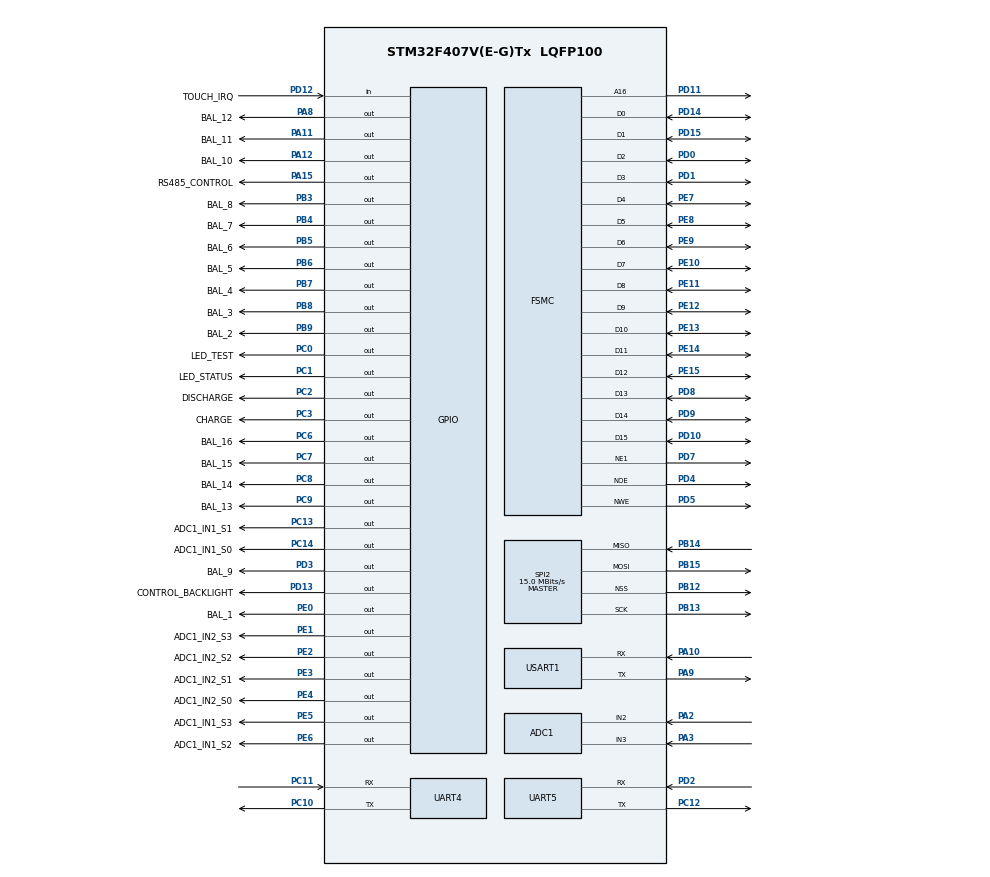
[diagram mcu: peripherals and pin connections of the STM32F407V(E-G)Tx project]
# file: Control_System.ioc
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ADC1.Channel-1\#ChannelRegularConversion=ADC_CHANNEL_2
ADC1.NbrOfConversionFlag=1
ADC1.Rank-1\#ChannelRegularConversion=1
ADC1.SamplingTime-1\#ChannelRegularConversion=ADC_SAMPLETIME_3CYCLES
ADC1.master=1
FSMC.AddressSetupTime1=0
FSMC.BusTurnAroundDuration1=0
FSMC.DataSetupTime1=1
Mcu.Family=STM32F4
Mcu.Name=STM32F407V(E-G)Tx
Mcu.Package=LQFP100
NVIC.PriorityGroup=NVIC_PRIORITYGROUP_4
PA10.Mode=Asynchronous
PA10.Signal=USART1_RX
PA11.GPIO_Label=BAL_11
PA11.Signal=GPIO_Output
PA12.GPIO_Label=BAL_10
PA12.Signal=GPIO_Output
PA13.Mode=Serial_Wire
PA13.Signal=SYS_JTMS-SWDIO
PA14.Mode=Serial_Wire
PA14.Signal=SYS_JTCK-SWCLK
PA15.GPIO_Label=RS485_CONTROL
PA15.Signal=GPIO_Output
PA2.Signal=ADCx_IN2
PA3.Signal=ADCx_IN3
PA8.GPIO_Label=BAL_12
PA8.Signal=GPIO_Output
PA9.Mode=Asynchronous
PA9.Signal=USART1_TX
PB12.Mode=NSS_Signal_Hard_Output
PB12.Signal=SPI2_NSS
PB13.Mode=Full_Duplex_Master
PB13.Signal=SPI2_SCK
PB14.Mode=Full_Duplex_Master
PB14.Signal=SPI2_MISO
PB15.Mode=Full_Duplex_Master
PB15.Signal=SPI2_MOSI
PB3.GPIO_Label=BAL_8
PB3.Signal=GPIO_Output
PB4.GPIO_Label=BAL_7
PB4.Signal=GPIO_Output
PB5.GPIO_Label=BAL_6
PB5.Signal=GPIO_Output
PB6.GPIO_Label=BAL_5
PB6.Signal=GPIO_Output
PB7.GPIO_Label=BAL_4
PB7.Signal=GPIO_Output
PB8.GPIO_Label=BAL_3
PB8.Signal=GPIO_Output
PB9.GPIO_Label=BAL_2
PB9.Signal=GPIO_Output
PC0.GPIO_Label=LED_TEST
PC0.Signal=GPIO_Output
PC1.GPIO_Label=LED_STATUS
PC1.Signal=GPIO_Output
PC10.Mode=Asynchronous
PC10.Signal=UART4_TX
PC11.Mode=Asynchronous
PC11.Signal=UART4_RX
PC12.Mode=Asynchronous
PC12.Signal=UART5_TX
PC13-ANTI_TAMP.GPIO_Label=ADC1_IN1_S1
PC13-ANTI_TAMP.Signal=GPIO_Output
PC14-OSC32_IN.GPIO_Label=ADC1_IN1_S0
PC14-OSC32_IN.Signal=GPIO_Output
PC2.GPIO_Label=DISCHARGE
PC2.Signal=GPIO_Output
PC3.GPIO_Label=CHARGE
PC3.Signal=GPIO_Output
PC6.GPIO_Label=BAL_16
PC6.Signal=GPIO_Output
PC7.GPIO_Label=BAL_15
PC7.Signal=GPIO_Output
PC8.GPIO_Label=BAL_14
PC8.Signal=GPIO_Output
PC9.GPIO_Label=BAL_13
PC9.Signal=GPIO_Output
PD0.Mode=16b-d1
PD0.Signal=FSMC_D2
PD1.Mode=16b-d1
PD1.Signal=FSMC_D3
PD10.Mode=16b-d1
PD10.Signal=FSMC_D15
PD11.Mode=A16_1
PD11.Signal=FSMC_A16
PD12.GPIO_Label=TOUCH_IRQ
PD12.Signal=GPIO_Input
PD13.GPIO_Label=CONTROL_BACKLIGHT
PD13.Signal=GPIO_Output
PD14.Mode=16b-d1
PD14.Signal=FSMC_D0
PD15.Mode=16b-d1
PD15.Signal=FSMC_D1
PD2.Mode=Asynchronous
PD2.Signal=UART5_RX
PD3.GPIO_Label=BAL_9
PD3.Signal=GPIO_Output
PD4.Mode=Lcd1
PD4.Signal=FSMC_NOE
PD5.Mode=Lcd1
PD5.Signal=FSMC_NWE
PD7.Mode=NorPsramChipSelect1_1
PD7.Signal=FSMC_NE1
PD8.Mode=16b-d1
PD8.Signal=FSMC_D13
PD9.Mode=16b-d1
PD9.Signal=FSMC_D14
PE0.GPIO_Label=BAL_1
PE0.Signal=GPIO_Output
PE1.GPIO_Label=ADC1_IN2_S3
PE1.Signal=GPIO_Output
PE10.Mode=16b-d1
PE10.Signal=FSMC_D7
PE11.Mode=16b-d1
PE11.Signal=FSMC_D8
PE12.Mode=16b-d1
PE12.Signal=FSMC_D9
PE13.Mode=16b-d1
PE13.Signal=FSMC_D10
PE14.Mode=16b-d1
PE14.Signal=FSMC_D11
PE15.Mode=16b-d1
PE15.Signal=FSMC_D12
PE2.GPIO_Label=ADC1_IN2_S2
PE2.Signal=GPIO_Output
PE3.GPIO_Label=ADC1_IN2_S1
PE3.Signal=GPIO_Output
PE4.GPIO_Label=ADC1_IN2_S0
PE4.Signal=GPIO_Output
PE5.GPIO_Label=ADC1_IN1_S3
PE5.Signal=GPIO_Output
PE6.GPIO_Label=ADC1_IN1_S2
PE6.Signal=GPIO_Output
PE7.Mode=16b-d1
PE7.Signal=FSMC_D4
PE8.Mode=16b-d1
PE8.Signal=FSMC_D5
PE9.Mode=16b-d1
PE9.Signal=FSMC_D6
PH0-OSC_IN.Mode=HSE-External-Oscillator
PH0-OSC_IN.Signal=RCC_OSC_IN
PH1-OSC_OUT.Mode=HSE-External-Oscillator
PH1-OSC_OUT.Signal=RCC_OSC_OUT
ProjectManager.HeapSize=0x200
ProjectManager.StackSize=0x400
ProjectManager.TargetToolchain=STM32CubeIDE
RCC.48MHZClocksFreq_Value=60000000
RCC.AHBFreq_Value=120000000
RCC.APB1CLKDivider=RCC_HCLK_DIV4
RCC.APB1Freq_Value=30000000
RCC.APB1TimFreq_Value=60000000
RCC.APB2CLKDivider=RCC_HCLK_DIV2
RCC.APB2Freq_Value=60000000
RCC.APB2TimFreq_Value=120000000
RCC.CortexFreq_Value=120000000
RCC.HCLKFreq_Value=120000000
RCC.HSE_VALUE=25000000
RCC.HSI_VALUE=16000000
RCC.LSE_VALUE=32768
RCC.PLLM=15
RCC.PLLN=144
RCC.PLLSourceVirtual=RCC_PLLSOURCE_HSE
RCC.SYSCLKFreq_VALUE=120000000
RCC.SYSCLKSource=RCC_SYSCLKSOURCE_PLLCLK
RCC.VCOOutputFreq_Value=240000000
SH.ADCx_IN2.0=ADC1_IN2,IN2
SH.ADCx_IN3.0=ADC1_IN3,IN3
SPI2.CalculateBaudRate=15.0 MBits/s
SPI2.Direction=SPI_DIRECTION_2LINES
SPI2.Mode=SPI_MODE_MASTER
SPI2.VirtualNSS=VM_NSSHARD
SPI2.VirtualType=VM_MASTER
UART4.VirtualMode=Asynchronous
UART5.VirtualMode=Asynchronous
USART1.VirtualMode=VM_ASYNC
board=custom

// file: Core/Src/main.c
/* USER CODE BEGIN Header */
/**
  ******************************************************************************
  * @file           : main.c
  * @brief          : Main program body
  ******************************************************************************
  * @attention
  *
  * Copyright (c) 2024 STMicroelectronics.
  * All rights reserved.
  *
  * This software is licensed under terms that can be found in the LICENSE file
  * in the root directory of this software component.
  * If no LICENSE file comes with this software, it is provided AS-IS.
  *
  ******************************************************************************
  */
/* USER CODE END Header */
#include "main.h"

/* USER CODE BEGIN Includes */
#include "lvgl.h"
/* USER CODE END Includes */

SRAM_HandleTypeDef hsram1;

void SystemClock_Config(void);
static void MX_GPIO_Init(void);
static void MX_ADC1_Init(void);
static void MX_FSMC_Init(void);
static void MX_SPI2_Init(void);
static void MX_UART4_Init(void);
static void MX_UART5_Init(void);
static void MX_USART1_UART_Init(void);

int main(void)
{

  /* MCU Configuration--------------------------------------------------------*/

  /* Reset of all peripherals, Initializes the Flash interface and the Systick. */
  HAL_Init();

  /* Configure the system clock */
  SystemClock_Config();

  /* Initialize all configured peripherals */
  MX_GPIO_Init();
  MX_ADC1_Init();
  MX_FSMC_Init();
  MX_SPI2_Init();
  MX_UART4_Init();
  MX_UART5_Init();
  MX_USART1_UART_Init();

  /* Infinite loop */
  while (1)
  {

  }
}

void SystemClock_Config(void)
{
  LL_FLASH_SetLatency(LL_FLASH_LATENCY_3);
  while(LL_FLASH_GetLatency()!= LL_FLASH_LATENCY_3)
  {
  }
  LL_PWR_SetRegulVoltageScaling(LL_PWR_REGU_VOLTAGE_SCALE1);
  LL_RCC_HSE_Enable();

   /* Wait till HSE is ready */
  while(LL_RCC_HSE_IsReady() != 1)
  {

  }
  LL_RCC_PLL_ConfigDomain_SYS(LL_RCC_PLLSOURCE_HSE, LL_RCC_PLLM_DIV_15, 144, LL_RCC_PLLP_DIV_2);
  LL_RCC_PLL_Enable();

   /* Wait till PLL is ready */
  while(LL_RCC_PLL_IsReady() != 1)
  {

  }
  while (LL_PWR_IsActiveFlag_VOS() == 0)
  {
  }
  LL_RCC_SetAHBPrescaler(LL_RCC_SYSCLK_DIV_1);
  LL_RCC_SetAPB1Prescaler(LL_RCC_APB1_DIV_4);
  LL_RCC_SetAPB2Prescaler(LL_RCC_APB2_DIV_2);
  LL_RCC_SetSysClkSource(LL_RCC_SYS_CLKSOURCE_PLL);

   /* Wait till System clock is ready */
  while(LL_RCC_GetSysClkSource() != LL_RCC_SYS_CLKSOURCE_STATUS_PLL)
  {

  }
  LL_SetSystemCoreClock(120000000);

   /* Update the time base */
  if (HAL_InitTick (TICK_INT_PRIORITY) != HAL_OK)
  {
    Error_Handler();
  }
}

static void MX_ADC1_Init(void)
{

  LL_ADC_InitTypeDef ADC_InitStruct = {0};
  LL_ADC_REG_InitTypeDef ADC_REG_InitStruct = {0};
  LL_ADC_CommonInitTypeDef ADC_CommonInitStruct = {0};

  LL_GPIO_InitTypeDef GPIO_InitStruct = {0};

  /* Peripheral clock enable */
  LL_APB2_GRP1_EnableClock(LL_APB2_GRP1_PERIPH_ADC1);

  LL_AHB1_GRP1_EnableClock(LL_AHB1_GRP1_PERIPH_GPIOA);
  /**ADC1 GPIO Configuration
  PA2   ------> ADC1_IN2
  PA3   ------> ADC1_IN3
  */
  GPIO_InitStruct.Pin = LL_GPIO_PIN_2|LL_GPIO_PIN_3;
  GPIO_InitStruct.Mode = LL_GPIO_MODE_ANALOG;
  GPIO_InitStruct.Pull = LL_GPIO_PULL_NO;
  LL_GPIO_Init(GPIOA, &GPIO_InitStruct);

  /** Common config
  */
  ADC_InitStruct.Resolution = LL_ADC_RESOLUTION_12B;
  ADC_InitStruct.DataAlignment = LL_ADC_DATA_ALIGN_RIGHT;
  ADC_InitStruct.SequencersScanMode = LL_ADC_SEQ_SCAN_DISABLE;
  LL_ADC_Init(ADC1, &ADC_InitStruct);
  ADC_REG_InitStruct.TriggerSource = LL_ADC_REG_TRIG_SOFTWARE;
  ADC_REG_InitStruct.SequencerLength = LL_ADC_REG_SEQ_SCAN_DISABLE;
  ADC_REG_InitStruct.SequencerDiscont = LL_ADC_REG_SEQ_DISCONT_DISABLE;
  ADC_REG_InitStruct.ContinuousMode = LL_ADC_REG_CONV_SINGLE;
  ADC_REG_InitStruct.DMATransfer = LL_ADC_REG_DMA_TRANSFER_NONE;
  LL_ADC_REG_Init(ADC1, &ADC_REG_InitStruct);
  LL_ADC_REG_SetFlagEndOfConversion(ADC1, LL_ADC_REG_FLAG_EOC_UNITARY_CONV);
  ADC_CommonInitStruct.CommonClock = LL_ADC_CLOCK_SYNC_PCLK_DIV2;
  ADC_CommonInitStruct.Multimode = LL_ADC_MULTI_INDEPENDENT;
  LL_ADC_CommonInit(__LL_ADC_COMMON_INSTANCE(ADC1), &ADC_CommonInitStruct);

  /** Configure Regular Channel
  */
  LL_ADC_REG_SetSequencerRanks(ADC1, LL_ADC_REG_RANK_1, LL_ADC_CHANNEL_2);
  LL_ADC_SetChannelSamplingTime(ADC1, LL_ADC_CHANNEL_2, LL_ADC_SAMPLINGTIME_3CYCLES);

}

static void MX_SPI2_Init(void)
{

  LL_SPI_InitTypeDef SPI_InitStruct = {0};

  LL_GPIO_InitTypeDef GPIO_InitStruct = {0};

  /* Peripheral clock enable */
  LL_APB1_GRP1_EnableClock(LL_APB1_GRP1_PERIPH_SPI2);

  LL_AHB1_GRP1_EnableClock(LL_AHB1_GRP1_PERIPH_GPIOB);
  /**SPI2 GPIO Configuration
  PB12   ------> SPI2_NSS
  PB13   ------> SPI2_SCK
  PB14   ------> SPI2_MISO
  PB15   ------> SPI2_MOSI
  */
  GPIO_InitStruct.Pin = LL_GPIO_PIN_12|LL_GPIO_PIN_13|LL_GPIO_PIN_14|LL_GPIO_PIN_15;
  GPIO_InitStruct.Mode = LL_GPIO_MODE_ALTERNATE;
  GPIO_InitStruct.Speed = LL_GPIO_SPEED_FREQ_VERY_HIGH;
  GPIO_InitStruct.OutputType = LL_GPIO_OUTPUT_PUSHPULL;
  GPIO_InitStruct.Pull = LL_GPIO_PULL_NO;
  GPIO_InitStruct.Alternate = LL_GPIO_AF_5;
  LL_GPIO_Init(GPIOB, &GPIO_InitStruct);

  /* SPI2 parameter configuration*/
  SPI_InitStruct.TransferDirection = LL_SPI_FULL_DUPLEX;
  SPI_InitStruct.Mode = LL_SPI_MODE_MASTER;
  SPI_InitStruct.DataWidth = LL_SPI_DATAWIDTH_8BIT;
  SPI_InitStruct.ClockPolarity = LL_SPI_POLARITY_LOW;
  SPI_InitStruct.ClockPhase = LL_SPI_PHASE_1EDGE;
  SPI_InitStruct.NSS = LL_SPI_NSS_HARD_OUTPUT;
  SPI_InitStruct.BaudRate = LL_SPI_BAUDRATEPRESCALER_DIV2;
  SPI_InitStruct.BitOrder = LL_SPI_MSB_FIRST;
  SPI_InitStruct.CRCCalculation = LL_SPI_CRCCALCULATION_DISABLE;
  SPI_InitStruct.CRCPoly = 10;
  LL_SPI_Init(SPI2, &SPI_InitStruct);
  LL_SPI_SetStandard(SPI2, LL_SPI_PROTOCOL_MOTOROLA);

}

static void MX_UART4_Init(void)
{

  LL_USART_InitTypeDef USART_InitStruct = {0};

  LL_GPIO_InitTypeDef GPIO_InitStruct = {0};

  /* Peripheral clock enable */
  LL_APB1_GRP1_EnableClock(LL_APB1_GRP1_PERIPH_UART4);

  LL_AHB1_GRP1_EnableClock(LL_AHB1_GRP1_PERIPH_GPIOC);
  /**UART4 GPIO Configuration
  PC10   ------> UART4_TX
  PC11   ------> UART4_RX
  */
  GPIO_InitStruct.Pin = LL_GPIO_PIN_10|LL_GPIO_PIN_11;
  GPIO_InitStruct.Mode = LL_GPIO_MODE_ALTERNATE;
  GPIO_InitStruct.Speed = LL_GPIO_SPEED_FREQ_VERY_HIGH;
  GPIO_InitStruct.OutputType = LL_GPIO_OUTPUT_PUSHPULL;
  GPIO_InitStruct.Pull = LL_GPIO_PULL_NO;
  GPIO_InitStruct.Alternate = LL_GPIO_AF_8;
  LL_GPIO_Init(GPIOC, &GPIO_InitStruct);

  USART_InitStruct.BaudRate = 115200;
  USART_InitStruct.DataWidth = LL_USART_DATAWIDTH_8B;
  USART_InitStruct.StopBits = LL_USART_STOPBITS_1;
  USART_InitStruct.Parity = LL_USART_PARITY_NONE;
  USART_InitStruct.TransferDirection = LL_USART_DIRECTION_TX_RX;
  USART_InitStruct.HardwareFlowControl = LL_USART_HWCONTROL_NONE;
  USART_InitStruct.OverSampling = LL_USART_OVERSAMPLING_16;
  LL_USART_Init(UART4, &USART_InitStruct);
  LL_USART_ConfigAsyncMode(UART4);
  LL_USART_Enable(UART4);

}

static void MX_UART5_Init(void)
{

  LL_USART_InitTypeDef USART_InitStruct = {0};

  LL_GPIO_InitTypeDef GPIO_InitStruct = {0};

  /* Peripheral clock enable */
  LL_APB1_GRP1_EnableClock(LL_APB1_GRP1_PERIPH_UART5);

  LL_AHB1_GRP1_EnableClock(LL_AHB1_GRP1_PERIPH_GPIOC);
  LL_AHB1_GRP1_EnableClock(LL_AHB1_GRP1_PERIPH_GPIOD);
  /**UART5 GPIO Configuration
  PC12   ------> UART5_TX
  PD2   ------> UART5_RX
  */
  GPIO_InitStruct.Pin = LL_GPIO_PIN_12;
  GPIO_InitStruct.Mode = LL_GPIO_MODE_ALTERNATE;
  GPIO_InitStruct.Speed = LL_GPIO_SPEED_FREQ_VERY_HIGH;
  GPIO_InitStruct.OutputType = LL_GPIO_OUTPUT_PUSHPULL;
  GPIO_InitStruct.Pull = LL_GPIO_PULL_NO;
  GPIO_InitStruct.Alternate = LL_GPIO_AF_8;
  LL_GPIO_Init(GPIOC, &GPIO_InitStruct);

  GPIO_InitStruct.Pin = LL_GPIO_PIN_2;
  GPIO_InitStruct.Mode = LL_GPIO_MODE_ALTERNATE;
  GPIO_InitStruct.Speed = LL_GPIO_SPEED_FREQ_VERY_HIGH;
  GPIO_InitStruct.OutputType = LL_GPIO_OUTPUT_PUSHPULL;
  GPIO_InitStruct.Pull = LL_GPIO_PULL_NO;
  GPIO_InitStruct.Alternate = LL_GPIO_AF_8;
  LL_GPIO_Init(GPIOD, &GPIO_InitStruct);

  USART_InitStruct.BaudRate = 115200;
  USART_InitStruct.DataWidth = LL_USART_DATAWIDTH_8B;
  USART_InitStruct.StopBits = LL_USART_STOPBITS_1;
  USART_InitStruct.Parity = LL_USART_PARITY_NONE;
  USART_InitStruct.TransferDirection = LL_USART_DIRECTION_TX_RX;
  USART_InitStruct.HardwareFlowControl = LL_USART_HWCONTROL_NONE;
  USART_InitStruct.OverSampling = LL_USART_OVERSAMPLING_16;
  LL_USART_Init(UART5, &USART_InitStruct);
  LL_USART_ConfigAsyncMode(UART5);
  LL_USART_Enable(UART5);

}

static void MX_USART1_UART_Init(void)
{

  LL_USART_InitTypeDef USART_InitStruct = {0};

  LL_GPIO_InitTypeDef GPIO_InitStruct = {0};

  /* Peripheral clock enable */
  LL_APB2_GRP1_EnableClock(LL_APB2_GRP1_PERIPH_USART1);

  LL_AHB1_GRP1_EnableClock(LL_AHB1_GRP1_PERIPH_GPIOA);
  /**USART1 GPIO Configuration
  PA9   ------> USART1_TX
  PA10   ------> USART1_RX
  */
  GPIO_InitStruct.Pin = LL_GPIO_PIN_9|LL_GPIO_PIN_10;
  GPIO_InitStruct.Mode = LL_GPIO_MODE_ALTERNATE;
  GPIO_InitStruct.Speed = LL_GPIO_SPEED_FREQ_VERY_HIGH;
  GPIO_InitStruct.OutputType = LL_GPIO_OUTPUT_PUSHPULL;
  GPIO_InitStruct.Pull = LL_GPIO_PULL_NO;
  GPIO_InitStruct.Alternate = LL_GPIO_AF_7;
  LL_GPIO_Init(GPIOA, &GPIO_InitStruct);

  USART_InitStruct.BaudRate = 115200;
  USART_InitStruct.DataWidth = LL_USART_DATAWIDTH_8B;
  USART_InitStruct.StopBits = LL_USART_STOPBITS_1;
  USART_InitStruct.Parity = LL_USART_PARITY_NONE;
  USART_InitStruct.TransferDirection = LL_USART_DIRECTION_TX_RX;
  USART_InitStruct.HardwareFlowControl = LL_USART_HWCONTROL_NONE;
  USART_InitStruct.OverSampling = LL_USART_OVERSAMPLING_16;
  LL_USART_Init(USART1, &USART_InitStruct);
  LL_USART_ConfigAsyncMode(USART1);
  LL_USART_Enable(USART1);

}

static void MX_GPIO_Init(void)
{
  LL_GPIO_InitTypeDef GPIO_InitStruct = {0};

  /* GPIO Ports Clock Enable */
  LL_AHB1_GRP1_EnableClock(LL_AHB1_GRP1_PERIPH_GPIOE);
  LL_AHB1_GRP1_EnableClock(LL_AHB1_GRP1_PERIPH_GPIOC);
  LL_AHB1_GRP1_EnableClock(LL_AHB1_GRP1_PERIPH_GPIOH);
  LL_AHB1_GRP1_EnableClock(LL_AHB1_GRP1_PERIPH_GPIOA);
  LL_AHB1_GRP1_EnableClock(LL_AHB1_GRP1_PERIPH_GPIOB);
  LL_AHB1_GRP1_EnableClock(LL_AHB1_GRP1_PERIPH_GPIOD);

  /**/
  LL_GPIO_ResetOutputPin(GPIOE, ADC1_IN2_S2_Pin|ADC1_IN2_S1_Pin|ADC1_IN2_S0_Pin|ADC1_IN1_S3_Pin
                          |ADC1_IN1_S2_Pin|BAL_1_Pin|ADC1_IN2_S3_Pin);

  /**/
  LL_GPIO_ResetOutputPin(GPIOC, ADC1_IN1_S1_Pin|ADC1_IN1_S0_Pin|LED_TEST_Pin|LED_STATUS_Pin
                          |DISCHARGE_Pin|CHARGE_Pin|BAL_16_Pin|BAL_15_Pin
                          |BAL_14_Pin|BAL_13_Pin);

  /**/
  LL_GPIO_ResetOutputPin(GPIOD, CONTROL_BACKLIGHT_Pin|BAL_9_Pin);

  /**/
  LL_GPIO_ResetOutputPin(GPIOA, BAL_12_Pin|BAL_11_Pin|BAL_10_Pin|RS485_CONTROL_Pin);

  /**/
  LL_GPIO_ResetOutputPin(GPIOB, BAL_8_Pin|BAL_7_Pin|BAL_6_Pin|BAL_5_Pin
                          |BAL_4_Pin|BAL_3_Pin|BAL_2_Pin);

  /**/
  GPIO_InitStruct.Pin = ADC1_IN2_S2_Pin|ADC1_IN2_S1_Pin|ADC1_IN2_S0_Pin|ADC1_IN1_S3_Pin
                          |ADC1_IN1_S2_Pin|BAL_1_Pin|ADC1_IN2_S3_Pin;
  GPIO_InitStruct.Mode = LL_GPIO_MODE_OUTPUT;
  GPIO_InitStruct.Speed = LL_GPIO_SPEED_FREQ_LOW;
  GPIO_InitStruct.OutputType = LL_GPIO_OUTPUT_PUSHPULL;
  GPIO_InitStruct.Pull = LL_GPIO_PULL_NO;
  LL_GPIO_Init(GPIOE, &GPIO_InitStruct);

  /**/
  GPIO_InitStruct.Pin = ADC1_IN1_S1_Pin|ADC1_IN1_S0_Pin|LED_TEST_Pin|LED_STATUS_Pin
                          |DISCHARGE_Pin|CHARGE_Pin|BAL_16_Pin|BAL_15_Pin
                          |BAL_14_Pin|BAL_13_Pin;
  GPIO_InitStruct.Mode = LL_GPIO_MODE_OUTPUT;
  GPIO_InitStruct.Speed = LL_GPIO_SPEED_FREQ_LOW;
  GPIO_InitStruct.OutputType = LL_GPIO_OUTPUT_PUSHPULL;
  GPIO_InitStruct.Pull = LL_GPIO_PULL_NO;
  LL_GPIO_Init(GPIOC, &GPIO_InitStruct);

  /**/
  GPIO_InitStruct.Pin = TOUCH_IRQ_Pin;
  GPIO_InitStruct.Mode = LL_GPIO_MODE_INPUT;
  GPIO_InitStruct.Pull = LL_GPIO_PULL_NO;
  LL_GPIO_Init(TOUCH_IRQ_GPIO_Port, &GPIO_InitStruct);

  /**/
  GPIO_InitStruct.Pin = CONTROL_BACKLIGHT_Pin|BAL_9_Pin;
  GPIO_InitStruct.Mode = LL_GPIO_MODE_OUTPUT;
  GPIO_InitStruct.Speed = LL_GPIO_SPEED_FREQ_LOW;
  GPIO_InitStruct.OutputType = LL_GPIO_OUTPUT_PUSHPULL;
  GPIO_InitStruct.Pull = LL_GPIO_PULL_NO;
  LL_GPIO_Init(GPIOD, &GPIO_InitStruct);

  /**/
  GPIO_InitStruct.Pin = BAL_12_Pin|BAL_11_Pin|BAL_10_Pin|RS485_CONTROL_Pin;
  GPIO_InitStruct.Mode = LL_GPIO_MODE_OUTPUT;
  GPIO_InitStruct.Speed = LL_GPIO_SPEED_FREQ_LOW;
  GPIO_InitStruct.OutputType = LL_GPIO_OUTPUT_PUSHPULL;
  GPIO_InitStruct.Pull = LL_GPIO_PULL_NO;
  LL_GPIO_Init(GPIOA, &GPIO_InitStruct);

  /**/
  GPIO_InitStruct.Pin = BAL_8_Pin|BAL_7_Pin|BAL_6_Pin|BAL_5_Pin
                          |BAL_4_Pin|BAL_3_Pin|BAL_2_Pin;
  GPIO_InitStruct.Mode = LL_GPIO_MODE_OUTPUT;
  GPIO_InitStruct.Speed = LL_GPIO_SPEED_FREQ_LOW;
  GPIO_InitStruct.OutputType = LL_GPIO_OUTPUT_PUSHPULL;
  GPIO_InitStruct.Pull = LL_GPIO_PULL_NO;
  LL_GPIO_Init(GPIOB, &GPIO_InitStruct);

}

/* FSMC initialization function */
static void MX_FSMC_Init(void)
{

  FSMC_NORSRAM_TimingTypeDef Timing = {0};

  /** Perform the SRAM1 memory initialization sequence
  */
  hsram1.Instance = FSMC_NORSRAM_DEVICE;
  hsram1.Extended = FSMC_NORSRAM_EXTENDED_DEVICE;
  /* hsram1.Init */
  hsram1.Init.NSBank = FSMC_NORSRAM_BANK1;
  hsram1.Init.DataAddressMux = FSMC_DATA_ADDRESS_MUX_DISABLE;
  hsram1.Init.MemoryType = FSMC_MEMORY_TYPE_SRAM;
  hsram1.Init.MemoryDataWidth = FSMC_NORSRAM_MEM_BUS_WIDTH_16;
  hsram1.Init.BurstAccessMode = FSMC_BURST_ACCESS_MODE_DISABLE;
  hsram1.Init.WaitSignalPolarity = FSMC_WAIT_SIGNAL_POLARITY_LOW;
  hsram1.Init.WrapMode = FSMC_WRAP_MODE_DISABLE;
  hsram1.Init.WaitSignalActive = FSMC_WAIT_TIMING_BEFORE_WS;
  hsram1.Init.WriteOperation = FSMC_WRITE_OPERATION_ENABLE;
  hsram1.Init.WaitSignal = FSMC_WAIT_SIGNAL_DISABLE;
  hsram1.Init.ExtendedMode = FSMC_EXTENDED_MODE_DISABLE;
  hsram1.Init.AsynchronousWait = FSMC_ASYNCHRONOUS_WAIT_DISABLE;
  hsram1.Init.WriteBurst = FSMC_WRITE_BURST_DISABLE;
  hsram1.Init.PageSize = FSMC_PAGE_SIZE_NONE;
  /* Timing */
  Timing.AddressSetupTime = 0;
  Timing.AddressHoldTime = 15;
  Timing.DataSetupTime = 1;
  Timing.BusTurnAroundDuration = 0;
  Timing.CLKDivision = 16;
  Timing.DataLatency = 17;
  Timing.AccessMode = FSMC_ACCESS_MODE_A;
  /* ExtTiming */

  if (HAL_SRAM_Init(&hsram1, &Timing, NULL) != HAL_OK)
  {
    Error_Handler( );
  }

}

void Error_Handler(void)
{
  __disable_irq();
  while (1)
  {
  }
}
